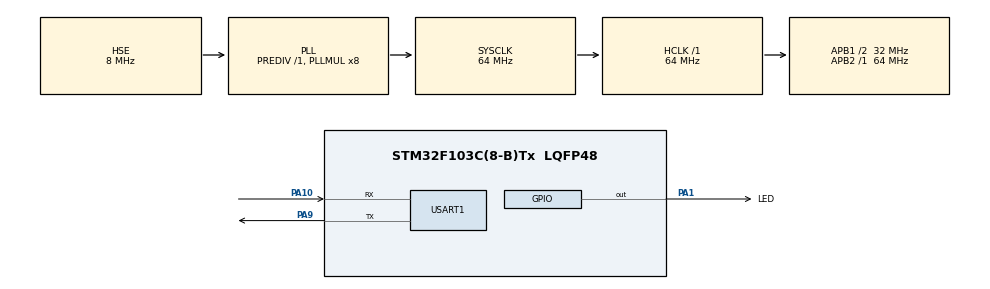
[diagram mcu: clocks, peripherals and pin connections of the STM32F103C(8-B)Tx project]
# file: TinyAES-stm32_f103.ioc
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Mcu.Family=STM32F1
Mcu.Name=STM32F103C(8-B)Tx
Mcu.Package=LQFP48
NVIC.PriorityGroup=NVIC_PRIORITYGROUP_4
PA1.GPIO_Label=LED
PA1.Signal=GPIO_Output
PA10.Mode=Asynchronous
PA10.Signal=USART1_RX
PA13.Mode=Serial_Wire
PA13.Signal=SYS_JTMS-SWDIO
PA14.Mode=Serial_Wire
PA14.Signal=SYS_JTCK-SWCLK
PA9.Mode=Asynchronous
PA9.Signal=USART1_TX
PD0-OSC_IN.Mode=HSE-External-Oscillator
PD0-OSC_IN.Signal=RCC_OSC_IN
PD1-OSC_OUT.Mode=HSE-External-Oscillator
PD1-OSC_OUT.Signal=RCC_OSC_OUT
ProjectManager.HeapSize=0x200
ProjectManager.StackSize=0x400
ProjectManager.TargetToolchain=SW4STM32
RCC.AHBFreq_Value=64000000
RCC.APB1CLKDivider=RCC_HCLK_DIV2
RCC.APB1Freq_Value=32000000
RCC.APB1TimFreq_Value=64000000
RCC.APB2Freq_Value=64000000
RCC.APB2TimFreq_Value=64000000
RCC.HCLKFreq_Value=64000000
RCC.PLLMUL=RCC_PLL_MUL8
RCC.PLLSourceVirtual=RCC_PLLSOURCE_HSE
RCC.SYSCLKFreq_VALUE=64000000
RCC.SYSCLKSource=RCC_SYSCLKSOURCE_PLLCLK
RCC.USBFreq_Value=64000000
USART1.VirtualMode=VM_ASYNC
board=custom

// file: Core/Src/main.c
/* USER CODE BEGIN Header */
/**
  ******************************************************************************
  * @file           : main.c
  * @brief          : Main program body
  ******************************************************************************
  * @attention
  *
  * <h2><center>&copy; Copyright (c) 2021 STMicroelectronics.
  * All rights reserved.</center></h2>
  *
  * This software component is licensed by ST under BSD 3-Clause license,
  * the "License"; You may not use this file except in compliance with the
  * License. You may obtain a copy of the License at:
  *                        opensource.org/licenses/BSD-3-Clause
  *
  ******************************************************************************
  */
/* USER CODE END Header */
#include "main.h"
#include "usart.h"
#include "gpio.h"

/* USER CODE BEGIN Includes */

	#include "stdio.h"
	#include <string.h>
	#include "aes.h"

/* USER CODE END Includes */

/* USER CODE BEGIN PD */

	#define CBC 1
	#define CTR 1
	#define ECB 1

/* USER CODE END PD */

/* USER CODE BEGIN PV */

	char 		uart_buff_char[0xFF];

/* USER CODE END PV */

void SystemClock_Config(void);
/* USER CODE BEGIN PFP */

	int TinyAES (void) ;
	static void phex(uint8_t* str);
	static int test_encrypt_cbc(void);
	static int test_decrypt_cbc(void);
	static int test_encrypt_ctr(void);
	static int test_decrypt_ctr(void);
	static int test_encrypt_ecb(void);
	static int test_decrypt_ecb(void);
	static void test_encrypt_ecb_verbose(void);

/* USER CODE END PFP */

int main(void)
{

  /* MCU Configuration--------------------------------------------------------*/

  /* Reset of all peripherals, Initializes the Flash interface and the Systick. */
  HAL_Init();

  /* Configure the system clock */
  SystemClock_Config();

  /* Initialize all configured peripherals */
  MX_GPIO_Init();
  MX_USART1_UART_Init();
  /* USER CODE BEGIN 2 */

	int cnt_int = 0 ;
	#define 	DATE_as_int_str 	(__DATE__)
	#define 	TIME_as_int_str 	(__TIME__)

	sprintf(uart_buff_char,"\r\n\r\n\tTinyAES stm32f103\r\nBuild: %s. Time: %s.\r\n" , DATE_as_int_str , TIME_as_int_str ) ;
	HAL_UART_Transmit( &huart1, (uint8_t *)uart_buff_char , strlen(uart_buff_char) , 100 ) ;

	int aes_res_int = TinyAES() ;
	sprintf(uart_buff_char,"TinyAES errors = %d \r\n" , aes_res_int ) ;
	HAL_UART_Transmit( &huart1, (uint8_t *)uart_buff_char , strlen(uart_buff_char) , 100 ) ;

  /* USER CODE END 2 */

  /* Infinite loop */
  /* USER CODE BEGIN WHILE */
  while (1)
  {

	HAL_Delay(1000);
	HAL_GPIO_TogglePin(LED_GPIO_Port, LED_Pin);
	sprintf(uart_buff_char,"cnt: %d\r" , cnt_int++ ) ;
	HAL_UART_Transmit( &huart1, (uint8_t *)uart_buff_char , strlen(uart_buff_char) , 100 ) ;

    /* USER CODE END WHILE */

  }
}

void SystemClock_Config(void)
{
  RCC_OscInitTypeDef RCC_OscInitStruct = {0};
  RCC_ClkInitTypeDef RCC_ClkInitStruct = {0};

  /** Initializes the RCC Oscillators according to the specified parameters
  * in the RCC_OscInitTypeDef structure.
  */
  RCC_OscInitStruct.OscillatorType = RCC_OSCILLATORTYPE_HSE;
  RCC_OscInitStruct.HSEState = RCC_HSE_ON;
  RCC_OscInitStruct.HSEPredivValue = RCC_HSE_PREDIV_DIV1;
  RCC_OscInitStruct.HSIState = RCC_HSI_ON;
  RCC_OscInitStruct.PLL.PLLState = RCC_PLL_ON;
  RCC_OscInitStruct.PLL.PLLSource = RCC_PLLSOURCE_HSE;
  RCC_OscInitStruct.PLL.PLLMUL = RCC_PLL_MUL8;
  if (HAL_RCC_OscConfig(&RCC_OscInitStruct) != HAL_OK)
  {
    Error_Handler();
  }
  /** Initializes the CPU, AHB and APB buses clocks
  */
  RCC_ClkInitStruct.ClockType = RCC_CLOCKTYPE_HCLK|RCC_CLOCKTYPE_SYSCLK
                              |RCC_CLOCKTYPE_PCLK1|RCC_CLOCKTYPE_PCLK2;
  RCC_ClkInitStruct.SYSCLKSource = RCC_SYSCLKSOURCE_PLLCLK;
  RCC_ClkInitStruct.AHBCLKDivider = RCC_SYSCLK_DIV1;
  RCC_ClkInitStruct.APB1CLKDivider = RCC_HCLK_DIV2;
  RCC_ClkInitStruct.APB2CLKDivider = RCC_HCLK_DIV1;

  if (HAL_RCC_ClockConfig(&RCC_ClkInitStruct, FLASH_LATENCY_2) != HAL_OK)
  {
    Error_Handler();
  }
}

/* USER CODE BEGIN 4 */

int TinyAES (void) {
    int exit = 0;
#if defined(AES256)
    sprintf(uart_buff_char,"Testing AES256\r\n");
    HAL_UART_Transmit( &huart1, (uint8_t *)uart_buff_char , strlen(uart_buff_char) , 100 ) ;
#elif defined(AES192)
    sprintf(uart_buff_char,"Testing AES192\r\n");
    HAL_UART_Transmit( &huart1, (uint8_t *)uart_buff_char , strlen(uart_buff_char) , 100 ) ;
#elif defined(AES128)
    sprintf(uart_buff_char,"Testing AES128\r\n");
    HAL_UART_Transmit( &huart1, (uint8_t *)uart_buff_char , strlen(uart_buff_char) , 100 ) ;
#else
    sprintf(uart_buff_char,"You need to specify a symbol between AES128, AES192 or AES256. Exiting\r\n");
    HAL_UART_Transmit( &huart1, (uint8_t *)uart_buff_char , strlen(uart_buff_char) , 100 ) ;
    return 0;
#endif

    exit = test_encrypt_cbc() + test_decrypt_cbc() +
	test_encrypt_ctr() + test_decrypt_ctr() +
	test_decrypt_ecb() + test_encrypt_ecb();
    test_encrypt_ecb_verbose();

    return exit;
}
// prints string as hex
static void phex(uint8_t* str) {

#if defined(AES256)
    uint8_t len = 32;
#elif defined(AES192)
    uint8_t len = 24;
#elif defined(AES128)
    uint8_t len = 16;
#endif

    unsigned char i;
    for (i = 0; i < len; ++i) {
        sprintf(uart_buff_char,"%.2x", str[i]);
        HAL_UART_Transmit( &huart1, (uint8_t *)uart_buff_char , strlen(uart_buff_char) , 100 ) ;
    }
    sprintf(uart_buff_char,"\r\n");
    HAL_UART_Transmit( &huart1, (uint8_t *)uart_buff_char , strlen(uart_buff_char) , 100 ) ;
}

static void test_encrypt_ecb_verbose(void) {
    // Example of more verbose verification

    uint8_t i;

    // 128bit key
    uint8_t key[16] =        { (uint8_t) 0x2b, (uint8_t) 0x7e, (uint8_t) 0x15, (uint8_t) 0x16, (uint8_t) 0x28, (uint8_t) 0xae, (uint8_t) 0xd2, (uint8_t) 0xa6, (uint8_t) 0xab, (uint8_t) 0xf7, (uint8_t) 0x15, (uint8_t) 0x88, (uint8_t) 0x09, (uint8_t) 0xcf, (uint8_t) 0x4f, (uint8_t) 0x3c };
    // 512bit text
    uint8_t plain_text[64] = { (uint8_t) 0x6b, (uint8_t) 0xc1, (uint8_t) 0xbe, (uint8_t) 0xe2, (uint8_t) 0x2e, (uint8_t) 0x40, (uint8_t) 0x9f, (uint8_t) 0x96, (uint8_t) 0xe9, (uint8_t) 0x3d, (uint8_t) 0x7e, (uint8_t) 0x11, (uint8_t) 0x73, (uint8_t) 0x93, (uint8_t) 0x17, (uint8_t) 0x2a,
                               (uint8_t) 0xae, (uint8_t) 0x2d, (uint8_t) 0x8a, (uint8_t) 0x57, (uint8_t) 0x1e, (uint8_t) 0x03, (uint8_t) 0xac, (uint8_t) 0x9c, (uint8_t) 0x9e, (uint8_t) 0xb7, (uint8_t) 0x6f, (uint8_t) 0xac, (uint8_t) 0x45, (uint8_t) 0xaf, (uint8_t) 0x8e, (uint8_t) 0x51,
                               (uint8_t) 0x30, (uint8_t) 0xc8, (uint8_t) 0x1c, (uint8_t) 0x46, (uint8_t) 0xa3, (uint8_t) 0x5c, (uint8_t) 0xe4, (uint8_t) 0x11, (uint8_t) 0xe5, (uint8_t) 0xfb, (uint8_t) 0xc1, (uint8_t) 0x19, (uint8_t) 0x1a, (uint8_t) 0x0a, (uint8_t) 0x52, (uint8_t) 0xef,
                               (uint8_t) 0xf6, (uint8_t) 0x9f, (uint8_t) 0x24, (uint8_t) 0x45, (uint8_t) 0xdf, (uint8_t) 0x4f, (uint8_t) 0x9b, (uint8_t) 0x17, (uint8_t) 0xad, (uint8_t) 0x2b, (uint8_t) 0x41, (uint8_t) 0x7b, (uint8_t) 0xe6, (uint8_t) 0x6c, (uint8_t) 0x37, (uint8_t) 0x10 };

    // print text to encrypt, key and IV
    sprintf(uart_buff_char,"ECB encrypt verbose:\r\n");
    HAL_UART_Transmit( &huart1, (uint8_t *)uart_buff_char , strlen(uart_buff_char) , 100 ) ;
    sprintf(uart_buff_char,"Plain text:\r\n");
    HAL_UART_Transmit( &huart1, (uint8_t *)uart_buff_char , strlen(uart_buff_char) , 100 ) ;
    for (i = (uint8_t) 0; i < (uint8_t) 4; ++i)
    {
        phex(plain_text + i * (uint8_t) 16);
    }
    sprintf(uart_buff_char,"\r\n");
    HAL_UART_Transmit( &huart1, (uint8_t *)uart_buff_char , strlen(uart_buff_char) , 100 ) ;

    sprintf(uart_buff_char,"Key:\r\n");
    HAL_UART_Transmit( &huart1, (uint8_t *)uart_buff_char , strlen(uart_buff_char) , 100 ) ;
    phex(key);
    sprintf(uart_buff_char,"\r\n");
    HAL_UART_Transmit( &huart1, (uint8_t *)uart_buff_char , strlen(uart_buff_char) , 100 ) ;

    // print the resulting cipher as 4 x 16 byte strings
    sprintf(uart_buff_char,"Cipher Text:\r\n");
    HAL_UART_Transmit( &huart1, (uint8_t *)uart_buff_char , strlen(uart_buff_char) , 100 ) ;

    struct AES_ctx ctx;
    AES_init_ctx(&ctx, key);

    for (i = 0; i < 4; ++i)
    {
      AES_ECB_encrypt(&ctx, plain_text + (i * 16));
      phex(plain_text + (i * 16));
    }
    sprintf(uart_buff_char,"\r\n");
    HAL_UART_Transmit( &huart1, (uint8_t *)uart_buff_char , strlen(uart_buff_char) , 100 ) ;
}

static int test_encrypt_ecb(void) {
#if defined(AES256)
    uint8_t key[] = { 0x60, 0x3d, 0xeb, 0x10, 0x15, 0xca, 0x71, 0xbe, 0x2b, 0x73, 0xae, 0xf0, 0x85, 0x7d, 0x77, 0x81,
                      0x1f, 0x35, 0x2c, 0x07, 0x3b, 0x61, 0x08, 0xd7, 0x2d, 0x98, 0x10, 0xa3, 0x09, 0x14, 0xdf, 0xf4 };
    uint8_t out[] = { 0xf3, 0xee, 0xd1, 0xbd, 0xb5, 0xd2, 0xa0, 0x3c, 0x06, 0x4b, 0x5a, 0x7e, 0x3d, 0xb1, 0x81, 0xf8 };
#elif defined(AES192)
    uint8_t key[] = { 0x8e, 0x73, 0xb0, 0xf7, 0xda, 0x0e, 0x64, 0x52, 0xc8, 0x10, 0xf3, 0x2b, 0x80, 0x90, 0x79, 0xe5,
                      0x62, 0xf8, 0xea, 0xd2, 0x52, 0x2c, 0x6b, 0x7b };
    uint8_t out[] = { 0xbd, 0x33, 0x4f, 0x1d, 0x6e, 0x45, 0xf2, 0x5f, 0xf7, 0x12, 0xa2, 0x14, 0x57, 0x1f, 0xa5, 0xcc };
#elif defined(AES128)
    uint8_t key[] = { 0x2b, 0x7e, 0x15, 0x16, 0x28, 0xae, 0xd2, 0xa6, 0xab, 0xf7, 0x15, 0x88, 0x09, 0xcf, 0x4f, 0x3c };
    uint8_t out[] = { 0x3a, 0xd7, 0x7b, 0xb4, 0x0d, 0x7a, 0x36, 0x60, 0xa8, 0x9e, 0xca, 0xf3, 0x24, 0x66, 0xef, 0x97 };
#endif

    uint8_t in[]  = { 0x6b, 0xc1, 0xbe, 0xe2, 0x2e, 0x40, 0x9f, 0x96, 0xe9, 0x3d, 0x7e, 0x11, 0x73, 0x93, 0x17, 0x2a };
    struct AES_ctx ctx;

    AES_init_ctx(&ctx, key);
    AES_ECB_encrypt(&ctx, in);

    sprintf(uart_buff_char,"ECB encrypt: ");
    HAL_UART_Transmit( &huart1, (uint8_t *)uart_buff_char , strlen(uart_buff_char) , 100 ) ;

    if (0 == memcmp((char*) out, (char*) in, 16)) {
        sprintf(uart_buff_char,"SUCCESS!\r\n");
        HAL_UART_Transmit( &huart1, (uint8_t *)uart_buff_char , strlen(uart_buff_char) , 100 ) ;
	return(0);
    } else {
        sprintf(uart_buff_char,"FAILURE!\n");
        HAL_UART_Transmit( &huart1, (uint8_t *)uart_buff_char , strlen(uart_buff_char) , 100 ) ;
	return(1);
    }
}

static int test_decrypt_cbc(void) {

#if defined(AES256)
    uint8_t key[] = { 0x60, 0x3d, 0xeb, 0x10, 0x15, 0xca, 0x71, 0xbe, 0x2b, 0x73, 0xae, 0xf0, 0x85, 0x7d, 0x77, 0x81,
                      0x1f, 0x35, 0x2c, 0x07, 0x3b, 0x61, 0x08, 0xd7, 0x2d, 0x98, 0x10, 0xa3, 0x09, 0x14, 0xdf, 0xf4 };
    uint8_t in[]  = { 0xf5, 0x8c, 0x4c, 0x04, 0xd6, 0xe5, 0xf1, 0xba, 0x77, 0x9e, 0xab, 0xfb, 0x5f, 0x7b, 0xfb, 0xd6,
                      0x9c, 0xfc, 0x4e, 0x96, 0x7e, 0xdb, 0x80, 0x8d, 0x67, 0x9f, 0x77, 0x7b, 0xc6, 0x70, 0x2c, 0x7d,
                      0x39, 0xf2, 0x33, 0x69, 0xa9, 0xd9, 0xba, 0xcf, 0xa5, 0x30, 0xe2, 0x63, 0x04, 0x23, 0x14, 0x61,
                      0xb2, 0xeb, 0x05, 0xe2, 0xc3, 0x9b, 0xe9, 0xfc, 0xda, 0x6c, 0x19, 0x07, 0x8c, 0x6a, 0x9d, 0x1b };
#elif defined(AES192)
    uint8_t key[] = { 0x8e, 0x73, 0xb0, 0xf7, 0xda, 0x0e, 0x64, 0x52, 0xc8, 0x10, 0xf3, 0x2b, 0x80, 0x90, 0x79, 0xe5, 0x62, 0xf8, 0xea, 0xd2, 0x52, 0x2c, 0x6b, 0x7b };
    uint8_t in[]  = { 0x4f, 0x02, 0x1d, 0xb2, 0x43, 0xbc, 0x63, 0x3d, 0x71, 0x78, 0x18, 0x3a, 0x9f, 0xa0, 0x71, 0xe8,
                      0xb4, 0xd9, 0xad, 0xa9, 0xad, 0x7d, 0xed, 0xf4, 0xe5, 0xe7, 0x38, 0x76, 0x3f, 0x69, 0x14, 0x5a,
                      0x57, 0x1b, 0x24, 0x20, 0x12, 0xfb, 0x7a, 0xe0, 0x7f, 0xa9, 0xba, 0xac, 0x3d, 0xf1, 0x02, 0xe0,
                      0x08, 0xb0, 0xe2, 0x79, 0x88, 0x59, 0x88, 0x81, 0xd9, 0x20, 0xa9, 0xe6, 0x4f, 0x56, 0x15, 0xcd };
#elif defined(AES128)
    uint8_t key[] = { 0x2b, 0x7e, 0x15, 0x16, 0x28, 0xae, 0xd2, 0xa6, 0xab, 0xf7, 0x15, 0x88, 0x09, 0xcf, 0x4f, 0x3c };
    uint8_t in[]  = { 0x76, 0x49, 0xab, 0xac, 0x81, 0x19, 0xb2, 0x46, 0xce, 0xe9, 0x8e, 0x9b, 0x12, 0xe9, 0x19, 0x7d,
                      0x50, 0x86, 0xcb, 0x9b, 0x50, 0x72, 0x19, 0xee, 0x95, 0xdb, 0x11, 0x3a, 0x91, 0x76, 0x78, 0xb2,
                      0x73, 0xbe, 0xd6, 0xb8, 0xe3, 0xc1, 0x74, 0x3b, 0x71, 0x16, 0xe6, 0x9e, 0x22, 0x22, 0x95, 0x16,
                      0x3f, 0xf1, 0xca, 0xa1, 0x68, 0x1f, 0xac, 0x09, 0x12, 0x0e, 0xca, 0x30, 0x75, 0x86, 0xe1, 0xa7 };
#endif
    uint8_t iv[]  = { 0x00, 0x01, 0x02, 0x03, 0x04, 0x05, 0x06, 0x07, 0x08, 0x09, 0x0a, 0x0b, 0x0c, 0x0d, 0x0e, 0x0f };
    uint8_t out[] = { 0x6b, 0xc1, 0xbe, 0xe2, 0x2e, 0x40, 0x9f, 0x96, 0xe9, 0x3d, 0x7e, 0x11, 0x73, 0x93, 0x17, 0x2a,
                      0xae, 0x2d, 0x8a, 0x57, 0x1e, 0x03, 0xac, 0x9c, 0x9e, 0xb7, 0x6f, 0xac, 0x45, 0xaf, 0x8e, 0x51,
                      0x30, 0xc8, 0x1c, 0x46, 0xa3, 0x5c, 0xe4, 0x11, 0xe5, 0xfb, 0xc1, 0x19, 0x1a, 0x0a, 0x52, 0xef,
                      0xf6, 0x9f, 0x24, 0x45, 0xdf, 0x4f, 0x9b, 0x17, 0xad, 0x2b, 0x41, 0x7b, 0xe6, 0x6c, 0x37, 0x10 };
//  uint8_t buffer[64];
    struct AES_ctx ctx;

    AES_init_ctx_iv(&ctx, key, iv);
    AES_CBC_decrypt_buffer(&ctx, in, 64);

    sprintf(uart_buff_char,"CBC decrypt: ");
    HAL_UART_Transmit( &huart1, (uint8_t *)uart_buff_char , strlen(uart_buff_char) , 100 ) ;

    if (0 == memcmp((char*) out, (char*) in, 64)) {
        sprintf(uart_buff_char,"SUCCESS!\r\n");
        HAL_UART_Transmit( &huart1, (uint8_t *)uart_buff_char , strlen(uart_buff_char) , 100 ) ;
	return(0);
    } else {
        sprintf(uart_buff_char,"FAILURE!\r\n");
        HAL_UART_Transmit( &huart1, (uint8_t *)uart_buff_char , strlen(uart_buff_char) , 100 ) ;
	return(1);
    }
}

static int test_encrypt_cbc(void) {
#if defined(AES256)
    uint8_t key[] = { 0x60, 0x3d, 0xeb, 0x10, 0x15, 0xca, 0x71, 0xbe, 0x2b, 0x73, 0xae, 0xf0, 0x85, 0x7d, 0x77, 0x81,
                      0x1f, 0x35, 0x2c, 0x07, 0x3b, 0x61, 0x08, 0xd7, 0x2d, 0x98, 0x10, 0xa3, 0x09, 0x14, 0xdf, 0xf4 };
    uint8_t out[] = { 0xf5, 0x8c, 0x4c, 0x04, 0xd6, 0xe5, 0xf1, 0xba, 0x77, 0x9e, 0xab, 0xfb, 0x5f, 0x7b, 0xfb, 0xd6,
                      0x9c, 0xfc, 0x4e, 0x96, 0x7e, 0xdb, 0x80, 0x8d, 0x67, 0x9f, 0x77, 0x7b, 0xc6, 0x70, 0x2c, 0x7d,
                      0x39, 0xf2, 0x33, 0x69, 0xa9, 0xd9, 0xba, 0xcf, 0xa5, 0x30, 0xe2, 0x63, 0x04, 0x23, 0x14, 0x61,
                      0xb2, 0xeb, 0x05, 0xe2, 0xc3, 0x9b, 0xe9, 0xfc, 0xda, 0x6c, 0x19, 0x07, 0x8c, 0x6a, 0x9d, 0x1b };
#elif defined(AES192)
    uint8_t key[] = { 0x8e, 0x73, 0xb0, 0xf7, 0xda, 0x0e, 0x64, 0x52, 0xc8, 0x10, 0xf3, 0x2b, 0x80, 0x90, 0x79, 0xe5, 0x62, 0xf8, 0xea, 0xd2, 0x52, 0x2c, 0x6b, 0x7b };
    uint8_t out[] = { 0x4f, 0x02, 0x1d, 0xb2, 0x43, 0xbc, 0x63, 0x3d, 0x71, 0x78, 0x18, 0x3a, 0x9f, 0xa0, 0x71, 0xe8,
                      0xb4, 0xd9, 0xad, 0xa9, 0xad, 0x7d, 0xed, 0xf4, 0xe5, 0xe7, 0x38, 0x76, 0x3f, 0x69, 0x14, 0x5a,
                      0x57, 0x1b, 0x24, 0x20, 0x12, 0xfb, 0x7a, 0xe0, 0x7f, 0xa9, 0xba, 0xac, 0x3d, 0xf1, 0x02, 0xe0,
                      0x08, 0xb0, 0xe2, 0x79, 0x88, 0x59, 0x88, 0x81, 0xd9, 0x20, 0xa9, 0xe6, 0x4f, 0x56, 0x15, 0xcd };
#elif defined(AES128)
    uint8_t key[] = { 0x2b, 0x7e, 0x15, 0x16, 0x28, 0xae, 0xd2, 0xa6, 0xab, 0xf7, 0x15, 0x88, 0x09, 0xcf, 0x4f, 0x3c };
    uint8_t out[] = { 0x76, 0x49, 0xab, 0xac, 0x81, 0x19, 0xb2, 0x46, 0xce, 0xe9, 0x8e, 0x9b, 0x12, 0xe9, 0x19, 0x7d,
                      0x50, 0x86, 0xcb, 0x9b, 0x50, 0x72, 0x19, 0xee, 0x95, 0xdb, 0x11, 0x3a, 0x91, 0x76, 0x78, 0xb2,
                      0x73, 0xbe, 0xd6, 0xb8, 0xe3, 0xc1, 0x74, 0x3b, 0x71, 0x16, 0xe6, 0x9e, 0x22, 0x22, 0x95, 0x16,
                      0x3f, 0xf1, 0xca, 0xa1, 0x68, 0x1f, 0xac, 0x09, 0x12, 0x0e, 0xca, 0x30, 0x75, 0x86, 0xe1, 0xa7 };
#endif
    uint8_t iv[]  = { 0x00, 0x01, 0x02, 0x03, 0x04, 0x05, 0x06, 0x07, 0x08, 0x09, 0x0a, 0x0b, 0x0c, 0x0d, 0x0e, 0x0f };
    uint8_t in[]  = { 0x6b, 0xc1, 0xbe, 0xe2, 0x2e, 0x40, 0x9f, 0x96, 0xe9, 0x3d, 0x7e, 0x11, 0x73, 0x93, 0x17, 0x2a,
                      0xae, 0x2d, 0x8a, 0x57, 0x1e, 0x03, 0xac, 0x9c, 0x9e, 0xb7, 0x6f, 0xac, 0x45, 0xaf, 0x8e, 0x51,
                      0x30, 0xc8, 0x1c, 0x46, 0xa3, 0x5c, 0xe4, 0x11, 0xe5, 0xfb, 0xc1, 0x19, 0x1a, 0x0a, 0x52, 0xef,
                      0xf6, 0x9f, 0x24, 0x45, 0xdf, 0x4f, 0x9b, 0x17, 0xad, 0x2b, 0x41, 0x7b, 0xe6, 0x6c, 0x37, 0x10 };
    struct AES_ctx ctx;

    AES_init_ctx_iv(&ctx, key, iv);
    AES_CBC_encrypt_buffer(&ctx, in, 64);

    sprintf(uart_buff_char,"CBC encrypt: ");
    HAL_UART_Transmit( &huart1, (uint8_t *)uart_buff_char , strlen(uart_buff_char) , 100 ) ;

    if (0 == memcmp((char*) out, (char*) in, 64)) {
        sprintf(uart_buff_char,"SUCCESS!\r\n");
        HAL_UART_Transmit( &huart1, (uint8_t *)uart_buff_char , strlen(uart_buff_char) , 100 ) ;
	return(0);
    } else {
        sprintf(uart_buff_char,"FAILURE!\n");
        HAL_UART_Transmit( &huart1, (uint8_t *)uart_buff_char , strlen(uart_buff_char) , 100 ) ;
	return(1);
    }
}

static int test_xcrypt_ctr(const char* xcrypt);

static int test_encrypt_ctr(void) {
    return test_xcrypt_ctr("encrypt");
}

static int test_decrypt_ctr(void) {
    return test_xcrypt_ctr("decrypt");
}

static int test_xcrypt_ctr(const char* xcrypt) {
#if defined(AES256)
    uint8_t key[32] = { 0x60, 0x3d, 0xeb, 0x10, 0x15, 0xca, 0x71, 0xbe, 0x2b, 0x73, 0xae, 0xf0, 0x85, 0x7d, 0x77, 0x81,
                        0x1f, 0x35, 0x2c, 0x07, 0x3b, 0x61, 0x08, 0xd7, 0x2d, 0x98, 0x10, 0xa3, 0x09, 0x14, 0xdf, 0xf4 };
    uint8_t in[64]  = { 0x60, 0x1e, 0xc3, 0x13, 0x77, 0x57, 0x89, 0xa5, 0xb7, 0xa7, 0xf5, 0x04, 0xbb, 0xf3, 0xd2, 0x28,
                        0xf4, 0x43, 0xe3, 0xca, 0x4d, 0x62, 0xb5, 0x9a, 0xca, 0x84, 0xe9, 0x90, 0xca, 0xca, 0xf5, 0xc5,
                        0x2b, 0x09, 0x30, 0xda, 0xa2, 0x3d, 0xe9, 0x4c, 0xe8, 0x70, 0x17, 0xba, 0x2d, 0x84, 0x98, 0x8d,
                        0xdf, 0xc9, 0xc5, 0x8d, 0xb6, 0x7a, 0xad, 0xa6, 0x13, 0xc2, 0xdd, 0x08, 0x45, 0x79, 0x41, 0xa6 };
#elif defined(AES192)
    uint8_t key[24] = { 0x8e, 0x73, 0xb0, 0xf7, 0xda, 0x0e, 0x64, 0x52, 0xc8, 0x10, 0xf3, 0x2b, 0x80, 0x90, 0x79, 0xe5,
                        0x62, 0xf8, 0xea, 0xd2, 0x52, 0x2c, 0x6b, 0x7b };
    uint8_t in[64]  = { 0x1a, 0xbc, 0x93, 0x24, 0x17, 0x52, 0x1c, 0xa2, 0x4f, 0x2b, 0x04, 0x59, 0xfe, 0x7e, 0x6e, 0x0b,
                        0x09, 0x03, 0x39, 0xec, 0x0a, 0xa6, 0xfa, 0xef, 0xd5, 0xcc, 0xc2, 0xc6, 0xf4, 0xce, 0x8e, 0x94,
                        0x1e, 0x36, 0xb2, 0x6b, 0xd1, 0xeb, 0xc6, 0x70, 0xd1, 0xbd, 0x1d, 0x66, 0x56, 0x20, 0xab, 0xf7,
                        0x4f, 0x78, 0xa7, 0xf6, 0xd2, 0x98, 0x09, 0x58, 0x5a, 0x97, 0xda, 0xec, 0x58, 0xc6, 0xb0, 0x50 };
#elif defined(AES128)
    uint8_t key[16] = { 0x2b, 0x7e, 0x15, 0x16, 0x28, 0xae, 0xd2, 0xa6, 0xab, 0xf7, 0x15, 0x88, 0x09, 0xcf, 0x4f, 0x3c };
    uint8_t in[64]  = { 0x87, 0x4d, 0x61, 0x91, 0xb6, 0x20, 0xe3, 0x26, 0x1b, 0xef, 0x68, 0x64, 0x99, 0x0d, 0xb6, 0xce,
                        0x98, 0x06, 0xf6, 0x6b, 0x79, 0x70, 0xfd, 0xff, 0x86, 0x17, 0x18, 0x7b, 0xb9, 0xff, 0xfd, 0xff,
                        0x5a, 0xe4, 0xdf, 0x3e, 0xdb, 0xd5, 0xd3, 0x5e, 0x5b, 0x4f, 0x09, 0x02, 0x0d, 0xb0, 0x3e, 0xab,
                        0x1e, 0x03, 0x1d, 0xda, 0x2f, 0xbe, 0x03, 0xd1, 0x79, 0x21, 0x70, 0xa0, 0xf3, 0x00, 0x9c, 0xee };
#endif
    uint8_t iv[16]  = { 0xf0, 0xf1, 0xf2, 0xf3, 0xf4, 0xf5, 0xf6, 0xf7, 0xf8, 0xf9, 0xfa, 0xfb, 0xfc, 0xfd, 0xfe, 0xff };
    uint8_t out[64] = { 0x6b, 0xc1, 0xbe, 0xe2, 0x2e, 0x40, 0x9f, 0x96, 0xe9, 0x3d, 0x7e, 0x11, 0x73, 0x93, 0x17, 0x2a,
                        0xae, 0x2d, 0x8a, 0x57, 0x1e, 0x03, 0xac, 0x9c, 0x9e, 0xb7, 0x6f, 0xac, 0x45, 0xaf, 0x8e, 0x51,
                        0x30, 0xc8, 0x1c, 0x46, 0xa3, 0x5c, 0xe4, 0x11, 0xe5, 0xfb, 0xc1, 0x19, 0x1a, 0x0a, 0x52, 0xef,
                        0xf6, 0x9f, 0x24, 0x45, 0xdf, 0x4f, 0x9b, 0x17, 0xad, 0x2b, 0x41, 0x7b, 0xe6, 0x6c, 0x37, 0x10 };
    struct AES_ctx ctx;

    AES_init_ctx_iv(&ctx, key, iv);
    AES_CTR_xcrypt_buffer(&ctx, in, 64);

    sprintf(uart_buff_char,"CTR %s: ", xcrypt);
    HAL_UART_Transmit( &huart1, (uint8_t *)uart_buff_char , strlen(uart_buff_char) , 100 ) ;

    if (0 == memcmp((char *) out, (char *) in, 64)) {
        sprintf(uart_buff_char,"SUCCESS!\r\n");
        HAL_UART_Transmit( &huart1, (uint8_t *)uart_buff_char , strlen(uart_buff_char) , 100 ) ;
	return(0);
    } else {
        sprintf(uart_buff_char,"FAILURE!\r\n");
        HAL_UART_Transmit( &huart1, (uint8_t *)uart_buff_char , strlen(uart_buff_char) , 100 ) ;
	return(1);
    }
}

static int test_decrypt_ecb(void) {
#if defined(AES256)
    uint8_t key[] = { 0x60, 0x3d, 0xeb, 0x10, 0x15, 0xca, 0x71, 0xbe, 0x2b, 0x73, 0xae, 0xf0, 0x85, 0x7d, 0x77, 0x81,
                      0x1f, 0x35, 0x2c, 0x07, 0x3b, 0x61, 0x08, 0xd7, 0x2d, 0x98, 0x10, 0xa3, 0x09, 0x14, 0xdf, 0xf4 };
    uint8_t in[]  = { 0xf3, 0xee, 0xd1, 0xbd, 0xb5, 0xd2, 0xa0, 0x3c, 0x06, 0x4b, 0x5a, 0x7e, 0x3d, 0xb1, 0x81, 0xf8 };
#elif defined(AES192)
    uint8_t key[] = { 0x8e, 0x73, 0xb0, 0xf7, 0xda, 0x0e, 0x64, 0x52, 0xc8, 0x10, 0xf3, 0x2b, 0x80, 0x90, 0x79, 0xe5,
                      0x62, 0xf8, 0xea, 0xd2, 0x52, 0x2c, 0x6b, 0x7b };
    uint8_t in[]  = { 0xbd, 0x33, 0x4f, 0x1d, 0x6e, 0x45, 0xf2, 0x5f, 0xf7, 0x12, 0xa2, 0x14, 0x57, 0x1f, 0xa5, 0xcc };
#elif defined(AES128)
    uint8_t key[] = { 0x2b, 0x7e, 0x15, 0x16, 0x28, 0xae, 0xd2, 0xa6, 0xab, 0xf7, 0x15, 0x88, 0x09, 0xcf, 0x4f, 0x3c };
    uint8_t in[]  = { 0x3a, 0xd7, 0x7b, 0xb4, 0x0d, 0x7a, 0x36, 0x60, 0xa8, 0x9e, 0xca, 0xf3, 0x24, 0x66, 0xef, 0x97 };
#endif

    uint8_t out[]   = { 0x6b, 0xc1, 0xbe, 0xe2, 0x2e, 0x40, 0x9f, 0x96, 0xe9, 0x3d, 0x7e, 0x11, 0x73, 0x93, 0x17, 0x2a };
    struct AES_ctx ctx;

    AES_init_ctx(&ctx, key);
    AES_ECB_decrypt(&ctx, in);

    sprintf(uart_buff_char,"ECB decrypt: ");
    HAL_UART_Transmit( &huart1, (uint8_t *)uart_buff_char , strlen(uart_buff_char) , 100 ) ;

    if (0 == memcmp((char*) out, (char*) in, 16)) {
        sprintf(uart_buff_char,"SUCCESS!\r\n");
        HAL_UART_Transmit( &huart1, (uint8_t *)uart_buff_char , strlen(uart_buff_char) , 100 ) ;
	return(0);
    } else {
        sprintf(uart_buff_char,"FAILURE!\r\n");
        HAL_UART_Transmit( &huart1, (uint8_t *)uart_buff_char , strlen(uart_buff_char) , 100 ) ;
	return(1);
    }
}

/* USER CODE END 4 */

void Error_Handler(void)
{
  __disable_irq();
  while (1)
  {
  }
}

/************************ (C) COPYRIGHT STMicroelectronics *****END OF FILE****/
